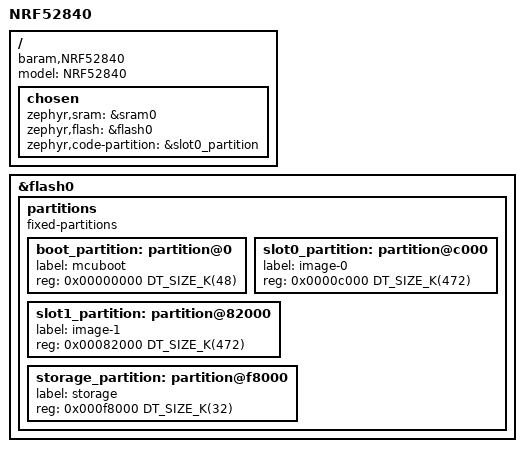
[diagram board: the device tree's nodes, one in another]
/dts-v1/;
#include <nordic/nrf52840_qiaa.dtsi>
#include "NRF52840-pinctrl.dtsi"

/ {
	model = "NRF52840";
	compatible = "baram,NRF52840";

	chosen {
		zephyr,sram = &sram0;
		zephyr,flash = &flash0;
		zephyr,code-partition = &slot0_partition;
	};
};

&flash0 {
	partitions {
		compatible = "fixed-partitions";
		#address-cells = <1>;
		#size-cells = <1>;

		boot_partition: partition@0 {
			label = "mcuboot";
			reg = <0x00000000 DT_SIZE_K(48)>;
		};

		slot0_partition: partition@c000 {
			label = "image-0";
			reg = <0x0000c000 DT_SIZE_K(472)>;
		};

		slot1_partition: partition@82000 {
			label = "image-1";
			reg = <0x00082000 DT_SIZE_K(472)>;
		};

		storage_partition: partition@f8000 {
			label = "storage";
			reg = <0x000f8000 DT_SIZE_K(32)>;
		};
	};
};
